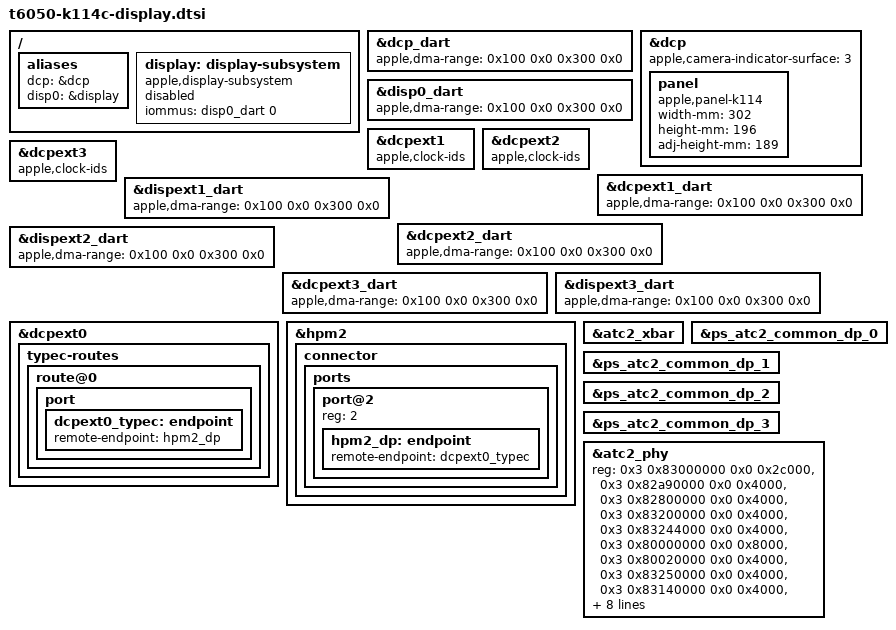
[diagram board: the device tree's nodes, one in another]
// SPDX-License-Identifier: GPL-2.0+ OR MIT
/*
 * K114c display: the boot loader's display hand-off nodes, and DisplayPort alt mode out of the
 * right USB-C port (ATC2) through dcpext0. DRAFT, not booted; modelled on t6050-j714s-gpu-panel.dtsi
 * and t6050-j714s-display.dtsi (the J714s drives this route; Aurora linux#1430, #1686, #1268-#1271).
 *
 * Everything stays disabled until the loader checks the ADT and the live DCP/DART state and
 * enables the nodes. Without that hand-off the panel stays on simpledrm.
 *
 * Not done here: the internal panel node (K114c's panel compatible is not in the binding yet,
 * Aurora linux#1648 adds the K-board pattern; the OS takes the size from the ADT when it has
 * it), the left-front port (ATC1) route, the HDMI connector, and the right port's
 * USB4 router. The ATC2 DP register block below is copied from the J714sAP file; its
 * dp-clock-source word and addresses must be checked against the K114c live ADT before a boot.
 */

/ {
	aliases {
		/* The loader writes apple,notch-height into the "dcp" alias */
		dcp = &dcp;
		disp0 = &display;
	};

	display: display-subsystem {
		compatible = "apple,display-subsystem";
		iommus = <&disp0_dart 0>;
		status = "disabled";
	};
};

/* ADT dart-dcp and dart-disp0: vm-base 1 TiB, vm-size 3 TiB */
&dcp_dart {
	apple,dma-range = <0x100 0x0 0x300 0x0>;
};

&disp0_dart {
	apple,dma-range = <0x100 0x0 0x300 0x0>;
};

&dcp {
	/*
	 * Swap slot 3 carries the kernel's software camera indicator; slots 0 and 1 are
	 * the userspace planes. Best effort, not a privacy guarantee.
	 */
	apple,camera-indicator-surface = <3>;

	/*
	 * The 14.2-inch tandem OLED panel. The size is the J714s panel's: the same 14-inch
	 * chassis. The OS takes the dimensions from the ADT when it has them; this K114c ADT
	 * has none.
	 */
	panel {
		compatible = "apple,panel-k114", "apple,panel";
		width-mm = <302>;
		height-mm = <196>;
		adj-height-mm = <189>;
	};
};

/* The ADT lists no clocks for the external engines (clock-ids = []) */
&dcpext1 {
	apple,clock-ids;
};

&dcpext2 {
	apple,clock-ids;
};

&dcpext3 {
	apple,clock-ids;
};

&dcpext1_dart {
	apple,dma-range = <0x100 0x0 0x300 0x0>;
};

&dispext1_dart {
	apple,dma-range = <0x100 0x0 0x300 0x0>;
};

&dcpext2_dart {
	apple,dma-range = <0x100 0x0 0x300 0x0>;
};

&dispext2_dart {
	apple,dma-range = <0x100 0x0 0x300 0x0>;
};

&dcpext3_dart {
	apple,dma-range = <0x100 0x0 0x300 0x0>;
};

&dispext3_dart {
	apple,dma-range = <0x100 0x0 0x300 0x0>;
};

/*
 * dcpext0's Type-C route: t6050-die0.dtsi sets the route (ATC2, crossbar index 0); the board
 * links it to the right port's connector.
 */
&dcpext0 {
	typec-routes {
		route@0 {
			port {
				dcpext0_typec: endpoint {
					remote-endpoint = <&hpm2_dp>;
				};
			};
		};
	};
};

&hpm2 {
	connector {
		ports {
			port@2 {
				reg = <2>;
				hpm2_dp: endpoint {
					remote-endpoint = <&dcpext0_typec>;
				};
			};
		};
	};
};

&atc2_xbar {
	status = "okay";
};

&ps_atc2_common_dp_0 {
	status = "okay";
};

&ps_atc2_common_dp_1 {
	status = "okay";
};

&ps_atc2_common_dp_2 {
	status = "okay";
};

&ps_atc2_common_dp_3 {
	status = "okay";
};

&atc2_phy {
	reg = <0x3 0x83000000 0x0 0x2c000>,
	      <0x3 0x82a90000 0x0 0x4000>,
	      <0x3 0x82800000 0x0 0x4000>,
	      <0x3 0x83200000 0x0 0x4000>,
	      <0x3 0x83244000 0x0 0x4000>,
	      <0x3 0x80000000 0x0 0x8000>,
	      <0x3 0x80020000 0x0 0x4000>,
	      <0x3 0x83250000 0x0 0x4000>,
	      <0x3 0x83140000 0x0 0x4000>,
	      <0x3 0x830c0000 0x0 0x10000>,
	      <0x3 0x82a84000 0x0 0x4000>,
	      <0x2 0x80000068 0x0 0x10>;
	reg-names = "core", "usb2phy", "usb2-digital", "reset", "fabric", "axi2af", "lioa",
		    "common-cfg", "usb-control", "firmware-data", "pipehandler",
		    "dp-clock-source";
	power-domains = <&ps_atc2_usb_aon>, <&ps_atc2_common>, <&ps_atc2_phymxwrap>,
			<&ps_atc2_usb>, <&ps_atc2_common_dp_0>, <&ps_atc2_common_dp_1>,
			<&ps_atc2_common_dp_2>, <&ps_atc2_common_dp_3>;
	power-domain-names = "usb-aon", "common", "wrapper", "usb", "dp0", "dp1", "dp2", "dp3";
};
